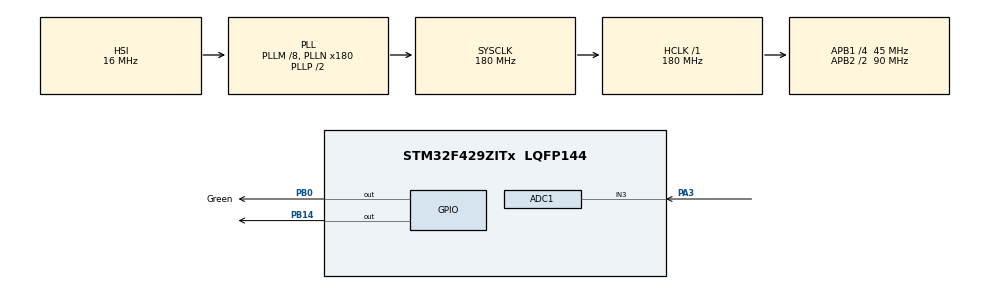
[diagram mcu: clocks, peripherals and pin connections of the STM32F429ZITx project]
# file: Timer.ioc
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ADC1.Channel-0\#ChannelRegularConversion=ADC_CHANNEL_3
ADC1.NbrOfConversionFlag=1
ADC1.Rank-0\#ChannelRegularConversion=1
ADC1.SamplingTime-0\#ChannelRegularConversion=ADC_SAMPLETIME_3CYCLES
ADC1.master=1
Mcu.Family=STM32F4
Mcu.Name=STM32F429ZITx
Mcu.Package=LQFP144
NVIC.PriorityGroup=NVIC_PRIORITYGROUP_4
NVIC.TIM2_IRQn=true\:0\:0\:false\:false\:true\:true\:true\:true
PA13.Mode=Serial_Wire
PA13.Signal=SYS_JTMS-SWDIO
PA14.Mode=Serial_Wire
PA14.Signal=SYS_JTCK-SWCLK
PA3.Signal=ADCx_IN3
PB0.GPIO_Label=Green
PB0.Signal=GPIO_Output
PB14.Signal=GPIO_Output
PH0/OSC_IN.Mode=HSE-External-Oscillator
PH0/OSC_IN.Signal=RCC_OSC_IN
PH1/OSC_OUT.Mode=HSE-External-Oscillator
PH1/OSC_OUT.Signal=RCC_OSC_OUT
ProjectManager.HeapSize=0x200
ProjectManager.StackSize=0x400
ProjectManager.TargetToolchain=STM32CubeIDE
RCC.48MHZClocksFreq_Value=90000000
RCC.AHBFreq_Value=180000000
RCC.APB1CLKDivider=RCC_HCLK_DIV4
RCC.APB1Freq_Value=45000000
RCC.APB1TimFreq_Value=90000000
RCC.APB2CLKDivider=RCC_HCLK_DIV2
RCC.APB2Freq_Value=90000000
RCC.APB2TimFreq_Value=180000000
RCC.CortexFreq_Value=180000000
RCC.HCLKFreq_Value=180000000
RCC.HSE_VALUE=8000000
RCC.HSI_VALUE=16000000
RCC.LSE_VALUE=32768
RCC.PLLM=8
RCC.PLLN=180
RCC.SYSCLKFreq_VALUE=180000000
RCC.SYSCLKSource=RCC_SYSCLKSOURCE_PLLCLK
RCC.VCOOutputFreq_Value=360000000
SH.ADCx_IN3.0=ADC1_IN3,IN3
TIM2.AutoReloadPreload=TIM_AUTORELOAD_PRELOAD_ENABLE
TIM2.ClockDivision=TIM_CLOCKDIVISION_DIV2
TIM2.Period=89999
TIM2.Prescaler=59999
VP_TIM2_VS_ClockSourceINT.Mode=Internal
board=custom

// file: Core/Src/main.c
/* USER CODE BEGIN Header */
/**
  ******************************************************************************
  * @file           : main.c
  * @brief          : Main program body
  ******************************************************************************
  * @attention
  *
  * Copyright (c) 2022 STMicroelectronics.
  * All rights reserved.
  *
  * This software is licensed under terms that can be found in the LICENSE file
  * in the root directory of this software component.
  * If no LICENSE file comes with this software, it is provided AS-IS.
  *
  ******************************************************************************
  */
/* USER CODE END Header */
#include "main.h"
#include "adc.h"
#include "tim.h"
#include "gpio.h"

/* USER CODE BEGIN PD */
uint16_t adc_fn(void);

void HAL_TIM_PeriodElapsedCallback(TIM_HandleTypeDef *htim);
/* USER CODE END PD */

/* USER CODE BEGIN PV */

uint32_t Wave_LUT[140] = {
    512, 537, 562, 587, 612, 637, 661, 685, 709, 732, 754, 776, 798, 818, 838,
    857, 875, 893, 909, 925, 939, 952, 965, 976, 986, 995, 1002, 1009, 1014, 1018,
    1021, 1023, 1023, 1022, 1020, 1016, 1012, 1006, 999, 990, 981, 970, 959, 946, 932,
    917, 901, 884, 866, 848, 828, 808, 787, 765, 743, 720, 697, 673, 649, 624,
    600, 575, 549, 524, 499, 474, 448, 423, 399, 374, 350, 326, 303, 280, 258,
    236, 215, 195, 175, 157, 139, 122, 106, 91, 77, 64, 53, 42, 33, 24,
    17, 11, 7, 3, 1, 0, 0, 2, 5, 9, 14, 21, 28, 37, 47,
    58, 71, 84, 98, 114, 130, 148, 166, 185, 205, 225, 247, 269, 291, 314,
    338, 362, 386, 411, 436, 461, 486, 511
};

uint32_t DestAddress = (uint32_t) &(TIM4->CCR4);
uint32_t TIM4_Ticks = 45000000 / (128 * 1000);

uint32_t raw;

uint16_t adc_volts = 0;

/* USER CODE END PV */

void SystemClock_Config(void);

/* USER CODE BEGIN 0 */

unsigned int PWM_Duty = 0;

/* USER CODE END 0 */

int main(void)
{

  /* MCU Configuration--------------------------------------------------------*/

  /* Reset of all peripherals, Initializes the Flash interface and the Systick. */
  HAL_Init();

  /* Configure the system clock */
  SystemClock_Config();

  /* Initialize all configured peripherals */
  MX_GPIO_Init();
  MX_TIM2_Init();
  MX_ADC1_Init();
  /* USER CODE BEGIN 2 */
 // HAL_TIM_Base_Start_IT(&htim2);

//
//  HAL_TIM_PWM_Start(&htim4, TIM_CHANNEL_3);
//  HAL_DMA_Start_IT(&hdma_tim4_ch3, (uint32_t)Wave_LUT, DestAddress, 128);
//

/*

  HAL_TIM_PWM_Start(&htim4, TIM_CHANNEL_3);
 TIM4->CCR4 = 20;
  PWM_Duty = 0;
  __HAL_TIM_SetCompare(&htim4, TIM_CHANNEL_3,PWM_Duty);
*/

  /* USER CODE END 2 */

  /* Infinite loop */
  /* USER CODE BEGIN WHILE */

  HAL_NVIC_SetPriority(TIM2_IRQn, 0, 0);
  HAL_NVIC_EnableIRQ(TIM2_IRQn);
  while (1)
  {
    /* USER CODE END WHILE */

    /* USER CODE BEGIN 3 */
//
//	  PWM_Duty++;
//	  __HAL_TIM_SetCompare(&htim4, TIM_CHANNEL_3,PWM_Duty);
//	  HAL_Delay(1);
//
/*
	  	      for(PWM_Duty=0; PWM_Duty<500; PWM_Duty++)
	  	      {
	  	        __HAL_TIM_SET_COMPARE(&htim4,TIM_CHANNEL_3, PWM_Duty);
	  	        HAL_Delay(1);
	  	      }
	  	      for(PWM_Duty=200; PWM_Duty>0; PWM_Duty--)
	  	      {
	  	        __HAL_TIM_SET_COMPARE(&htim4,TIM_CHANNEL_3, PWM_Duty);
	  	        HAL_Delay(1);
	  	      }
*/

  }
  /* USER CODE END 3 */
}

void SystemClock_Config(void)
{
  RCC_OscInitTypeDef RCC_OscInitStruct = {0};
  RCC_ClkInitTypeDef RCC_ClkInitStruct = {0};

  /** Configure the main internal regulator output voltage
  */
  __HAL_RCC_PWR_CLK_ENABLE();
  __HAL_PWR_VOLTAGESCALING_CONFIG(PWR_REGULATOR_VOLTAGE_SCALE1);

  /** Initializes the RCC Oscillators according to the specified parameters
  * in the RCC_OscInitTypeDef structure.
  */
  RCC_OscInitStruct.OscillatorType = RCC_OSCILLATORTYPE_HSI;
  RCC_OscInitStruct.HSIState = RCC_HSI_ON;
  RCC_OscInitStruct.HSICalibrationValue = RCC_HSICALIBRATION_DEFAULT;
  RCC_OscInitStruct.PLL.PLLState = RCC_PLL_ON;
  RCC_OscInitStruct.PLL.PLLSource = RCC_PLLSOURCE_HSI;
  RCC_OscInitStruct.PLL.PLLM = 8;
  RCC_OscInitStruct.PLL.PLLN = 180;
  RCC_OscInitStruct.PLL.PLLP = RCC_PLLP_DIV2;
  RCC_OscInitStruct.PLL.PLLQ = 4;
  if (HAL_RCC_OscConfig(&RCC_OscInitStruct) != HAL_OK)
  {
    Error_Handler();
  }

  /** Activate the Over-Drive mode
  */
  if (HAL_PWREx_EnableOverDrive() != HAL_OK)
  {
    Error_Handler();
  }

  /** Initializes the CPU, AHB and APB buses clocks
  */
  RCC_ClkInitStruct.ClockType = RCC_CLOCKTYPE_HCLK|RCC_CLOCKTYPE_SYSCLK
                              |RCC_CLOCKTYPE_PCLK1|RCC_CLOCKTYPE_PCLK2;
  RCC_ClkInitStruct.SYSCLKSource = RCC_SYSCLKSOURCE_PLLCLK;
  RCC_ClkInitStruct.AHBCLKDivider = RCC_SYSCLK_DIV1;
  RCC_ClkInitStruct.APB1CLKDivider = RCC_HCLK_DIV4;
  RCC_ClkInitStruct.APB2CLKDivider = RCC_HCLK_DIV2;

  if (HAL_RCC_ClockConfig(&RCC_ClkInitStruct, FLASH_LATENCY_5) != HAL_OK)
  {
    Error_Handler();
  }
}

/* USER CODE BEGIN 4 */
//
//uint16_t adc_fn(void)
//{
//
//       HAL_ADC_Start(&hadc1);
//       HAL_ADC_PollForConversion(&hadc1, HAL_MAX_DELAY);
//       raw = HAL_ADC_GetValue(&hadc1);
//       HAL_ADC_Stop(&hadc1);
//
//       return raw;
//}

void HAL_TIM_PeriodElapsedCallback(TIM_HandleTypeDef *htim)
{
	if(htim->Instance == TIM2)
	{

		HAL_GPIO_TogglePin(GPIOB,Green_Pin);
		HAL_GPIO_TogglePin(GPIOB, GPIO_PIN_14);

		}

	}

/* USER CODE END 4 */

void Error_Handler(void)
{
  __disable_irq();
  while (1)
  {
  }
}
